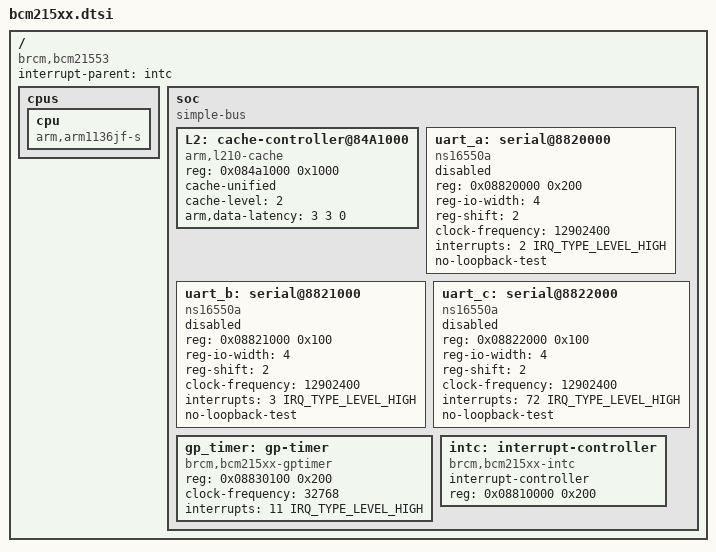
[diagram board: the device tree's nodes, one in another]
// SPDX-License-Identifier: GPL-2.0-only
/* Device tree for BCM215xx-series ARM SoCs. */

/dts-v1/;

#include <dt-bindings/interrupt-controller/irq.h>

/ {
	compatible = "brcm,bcm21553", "brcm,bcm215xx";
	interrupt-parent = <&intc>;
	#address-cells = <1>;
	#size-cells = <1>;

	cpus {
		#address-cells = <0>;
		#size-cells = <0>;

		cpu {
			compatible = "arm,arm1136jf-s";
			device_type = "cpu";
		};
	};

	soc {
		compatible = "simple-bus";
		#address-cells = <1>;
		#size-cells = <1>;
		ranges;

		L2: cache-controller@84A1000 {
			compatible = "arm,l210-cache";
			reg = <0x084a1000 0x1000>;
			cache-unified;
			cache-level = <2>;
			arm,data-latency = <3 3 0>;
		};

		uart_a: serial@8820000 {
			compatible = "ns16550a";
			reg = <0x08820000 0x200>;
			reg-io-width = <4>;
			reg-shift = <2>;
			// TODO: Actual clock.
			clock-frequency = <12902400>;
			interrupts = <2 IRQ_TYPE_LEVEL_HIGH>;
			no-loopback-test;
			status = "disabled";
		};

		uart_b: serial@8821000 {
			compatible = "ns16550a";
			reg = <0x08821000 0x100>;
			reg-io-width = <4>;
			reg-shift = <2>;
			// TODO: Actual clock.
			clock-frequency = <12902400>;
			interrupts = <3 IRQ_TYPE_LEVEL_HIGH>;
			no-loopback-test;
			status = "disabled";
		};

		uart_c: serial@8822000 {
			compatible = "ns16550a";
			reg = <0x08822000 0x100>;
			reg-io-width = <4>;
			reg-shift = <2>;
			// TODO: Actual clock.
			clock-frequency = <12902400>;
			interrupts = <72 IRQ_TYPE_LEVEL_HIGH>;
			no-loopback-test;
			status = "disabled";
		};

		gp_timer: gp-timer {
			compatible = "brcm,bcm215xx-gptimer";
			reg = <0x08830100 0x200>;
			clock-frequency = <32768>;
			interrupts = <11 IRQ_TYPE_LEVEL_HIGH>;
		};

		intc: interrupt-controller {
			compatible = "brcm,bcm215xx-intc";
			#interrupt-cells = <2>;
			interrupt-controller;

			reg = <0x08810000 0x200>;
		};
	};
};

